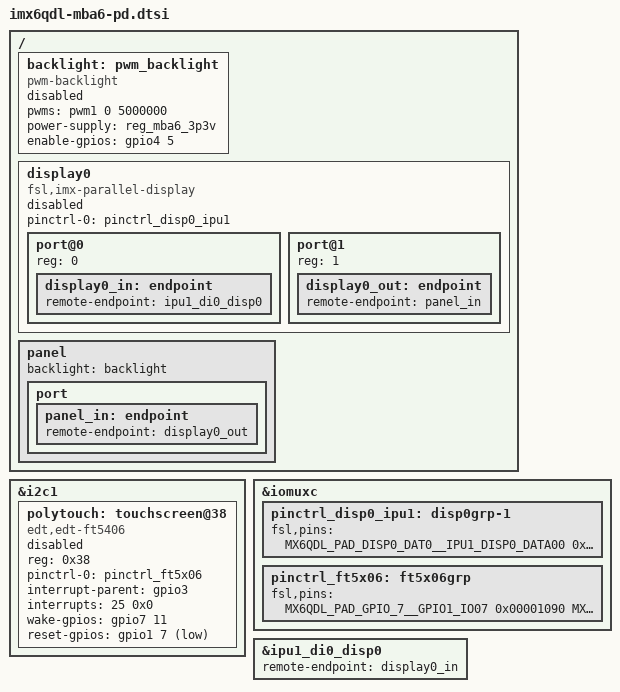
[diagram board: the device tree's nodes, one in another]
// SPDX-License-Identifier: (GPL-2.0-or-later OR MIT)
/*
 * Copyright 2014 TQ-Systems GmbH
 * Author: Markus Niebel <Markus.Niebel@tq-group.com>
 */

/ {
	backlight: pwm_backlight {
		compatible = "pwm-backlight";
		pwms = <&pwm1 0 5000000>;
		power-supply = <&reg_mba6_3p3v>;
		enable-gpios = <&gpio4 5 GPIO_ACTIVE_HIGH>;
		status = "disabled";
	};

	display0: display0 {
		compatible = "fsl,imx-parallel-display";
		#address-cells = <1>;
		#size-cells = <0>;
		pinctrl-names = "default";
		pinctrl-0 = <&pinctrl_disp0_ipu1>;
		status = "disabled";

		port@0 {
			reg = <0>;

			display0_in: endpoint {
				remote-endpoint = <&ipu1_di0_disp0>;
			};
		};

		port@1 {
			reg = <1>;

			display0_out: endpoint {
				remote-endpoint = <&panel_in>;
			};
		};
	};

	panel: panel {
		backlight = <&backlight>;

		port {
			panel_in: endpoint {
				remote-endpoint = <&display0_out>;
			};
		};
	};
};

&i2c1 {
	polytouch: touchscreen@38 {
		compatible = "edt,edt-ft5406", "edt,edt-ft5x06";
		reg = <0x38>;
		pinctrl-names = "default";
		pinctrl-0 = <&pinctrl_ft5x06>;
		interrupt-parent = <&gpio3>;
		interrupts = <25 0x0>;
		/* LCD.PWR_EN -> TSC /WAKE */
		wake-gpios = <&gpio7 11 GPIO_ACTIVE_HIGH>;
		/* LCD.RESET -> TSC /RST */
		reset-gpios = <&gpio1 7 GPIO_ACTIVE_LOW>;

		status = "disabled";
	};
};

&iomuxc {
	pinctrl_disp0_ipu1: disp0grp-1 {
		fsl,pins = <
			MX6QDL_PAD_DISP0_DAT0__IPU1_DISP0_DATA00	0x1b0b0
			MX6QDL_PAD_DISP0_DAT1__IPU1_DISP0_DATA01	0x1b0b0
			MX6QDL_PAD_DISP0_DAT2__IPU1_DISP0_DATA02	0x1b0b0
			MX6QDL_PAD_DISP0_DAT3__IPU1_DISP0_DATA03	0x1b0b0
			MX6QDL_PAD_DISP0_DAT4__IPU1_DISP0_DATA04	0x1b0b0
			MX6QDL_PAD_DISP0_DAT5__IPU1_DISP0_DATA05	0x1b0b0
			MX6QDL_PAD_DISP0_DAT6__IPU1_DISP0_DATA06	0x1b0b0
			MX6QDL_PAD_DISP0_DAT7__IPU1_DISP0_DATA07	0x1b0b0
			MX6QDL_PAD_DISP0_DAT8__IPU1_DISP0_DATA08	0x1b0b0
			MX6QDL_PAD_DISP0_DAT9__IPU1_DISP0_DATA09	0x1b0b0
			MX6QDL_PAD_DISP0_DAT10__IPU1_DISP0_DATA10	0x1b0b0
			MX6QDL_PAD_DISP0_DAT11__IPU1_DISP0_DATA11	0x1b0b0
			MX6QDL_PAD_DISP0_DAT12__IPU1_DISP0_DATA12	0x1b0b0
			MX6QDL_PAD_DISP0_DAT13__IPU1_DISP0_DATA13	0x1b0b0
			MX6QDL_PAD_DISP0_DAT14__IPU1_DISP0_DATA14	0x1b0b0
			MX6QDL_PAD_DISP0_DAT15__IPU1_DISP0_DATA15	0x1b0b0
			MX6QDL_PAD_DISP0_DAT16__IPU1_DISP0_DATA16	0x1b0b0
			MX6QDL_PAD_DISP0_DAT17__IPU1_DISP0_DATA17	0x1b0b0
			MX6QDL_PAD_DISP0_DAT18__IPU1_DISP0_DATA18	0x1b0b0
			MX6QDL_PAD_DISP0_DAT19__IPU1_DISP0_DATA19	0x1b0b0
			MX6QDL_PAD_DISP0_DAT20__IPU1_DISP0_DATA20	0x1b0b0
			MX6QDL_PAD_DISP0_DAT21__IPU1_DISP0_DATA21	0x1b0b0
			MX6QDL_PAD_DISP0_DAT22__IPU1_DISP0_DATA22	0x1b0b0
			MX6QDL_PAD_DISP0_DAT23__IPU1_DISP0_DATA23	0x1b0b0
			MX6QDL_PAD_DI0_PIN2__IPU1_DI0_PIN02		0x1b0b0
			MX6QDL_PAD_DI0_PIN3__IPU1_DI0_PIN03		0x1b0b0
			MX6QDL_PAD_DI0_PIN15__IPU1_DI0_PIN15		0x1b0b0
			MX6QDL_PAD_DI0_DISP_CLK__IPU1_DI0_DISP_CLK	0x1b0b0
		>;
	};

	pinctrl_ft5x06: ft5x06grp {
		fsl,pins = <
			/* LCD.RESET -> TSC /RST */
			MX6QDL_PAD_GPIO_7__GPIO1_IO07  0x00001090
			/* LCD.PWR_EN -> TSC /WAKE */
			MX6QDL_PAD_GPIO_16__GPIO7_IO11 0x00001090
			/* TSC Interrupt line: HYS, PKE, SPEED MED, DSE 240 OHM */
			MX6QDL_PAD_EIM_D25__GPIO3_IO25 0x00013088
		>;
	};
};

&ipu1_di0_disp0 {
	remote-endpoint = <&display0_in>;
};
